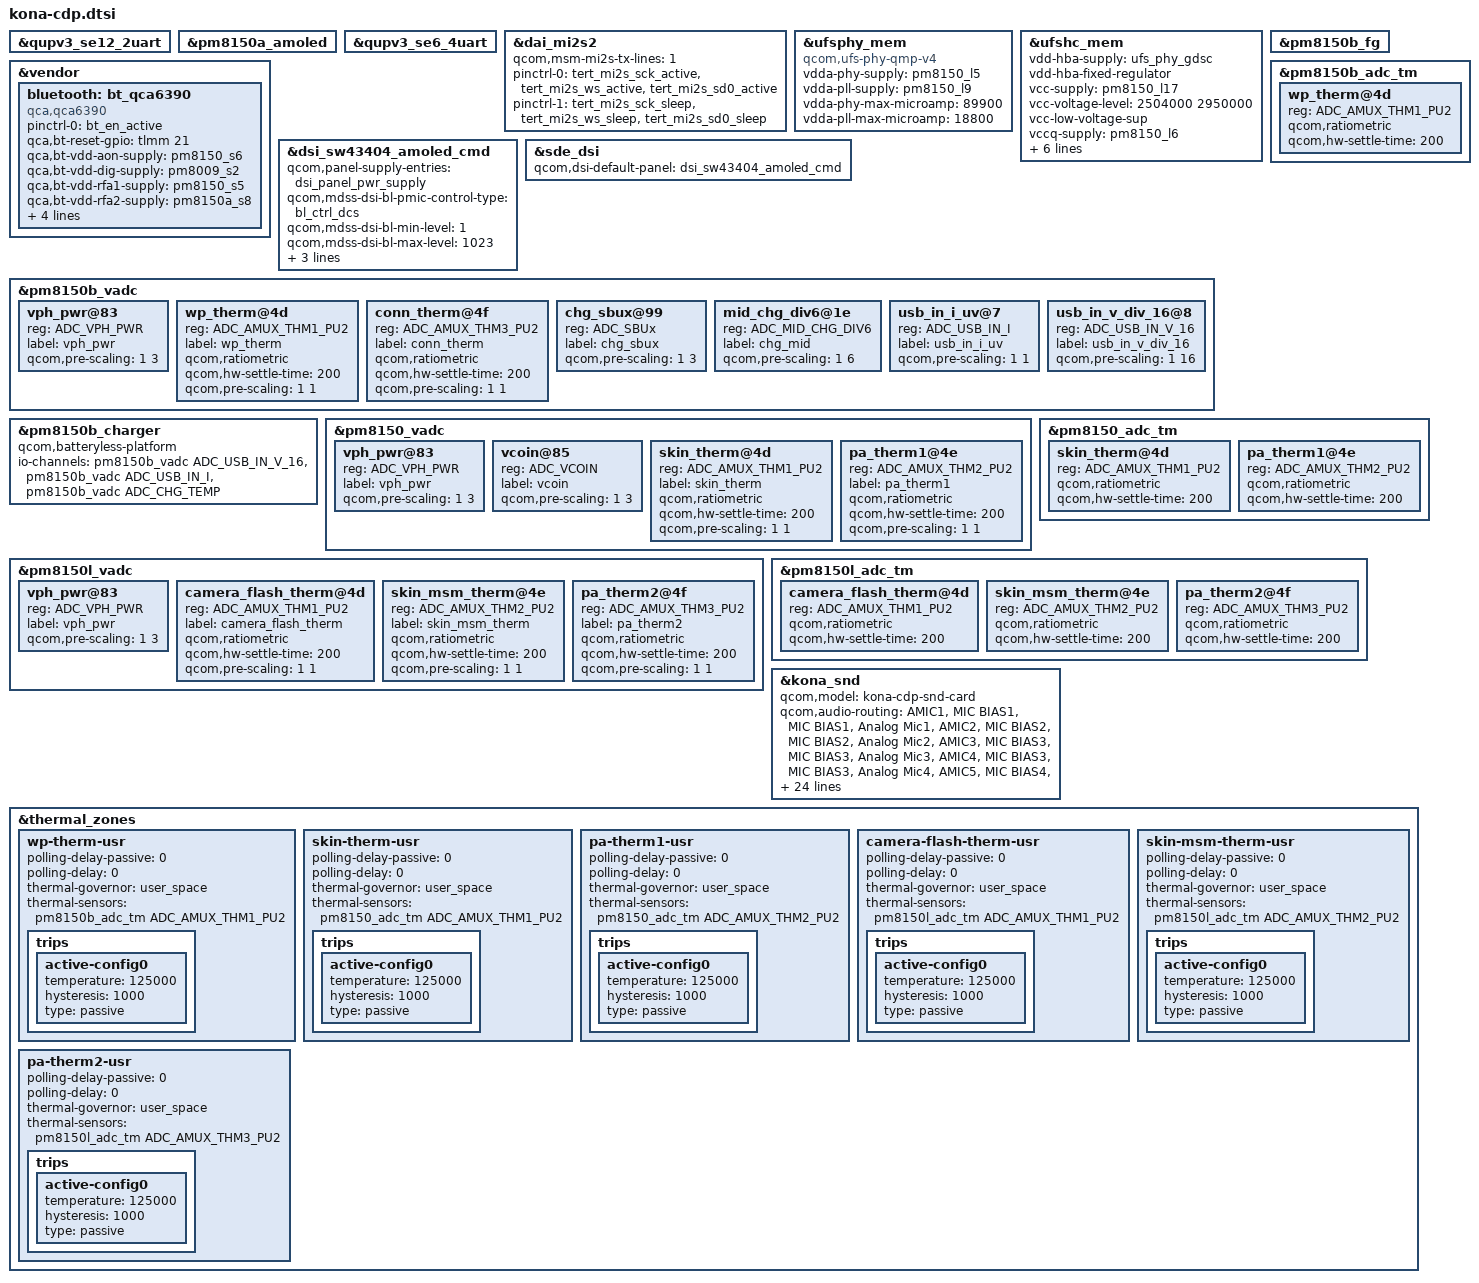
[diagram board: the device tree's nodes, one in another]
// SPDX-License-Identifier: GPL-2.0-only
/*
 * Copyright (c) 2018-2019, The Linux Foundation. All rights reserved.
 */


#include "kona-pmic-overlay.dtsi"
#include "kona-sde-display.dtsi"
#include "kona-camera-sensor-cdp.dtsi"
#include "kona-audio-overlay.dtsi"

&qupv3_se12_2uart {
	status = "ok";
};

&pm8150a_amoled {
	status = "ok";
};

&qupv3_se6_4uart {
	status = "ok";
};

&dai_mi2s2 {
	qcom,msm-mi2s-tx-lines = <1>;
	pinctrl-names = "default", "sleep";
	pinctrl-0 = <&tert_mi2s_sck_active &tert_mi2s_ws_active
			&tert_mi2s_sd0_active>;
	pinctrl-1 = <&tert_mi2s_sck_sleep &tert_mi2s_ws_sleep
			&tert_mi2s_sd0_sleep>;
};

&ufsphy_mem {
	compatible = "qcom,ufs-phy-qmp-v4";

	vdda-phy-supply = <&pm8150_l5>;
	vdda-pll-supply = <&pm8150_l9>;
	vdda-phy-max-microamp = <89900>;
	vdda-pll-max-microamp = <18800>;

	status = "ok";
};

&ufshc_mem {
	vdd-hba-supply = <&ufs_phy_gdsc>;
	vdd-hba-fixed-regulator;
	vcc-supply = <&pm8150_l17>;
	vcc-voltage-level = <2504000 2950000>;
	vcc-low-voltage-sup;
	vccq-supply = <&pm8150_l6>;
	vccq2-supply = <&pm8150_s4>;
	vccq-max-microamp = <800000>;
	vcc-max-microamp = <800000>;
	vccq2-max-microamp = <800000>;

	qcom,vddp-ref-clk-supply = <&pm8150_l6>;
	qcom,vddp-ref-clk-max-microamp = <100>;

	status = "ok";
};

&vendor {
	bluetooth: bt_qca6390 {
		compatible = "qca,qca6390";
		pinctrl-names = "default";
		pinctrl-0 = <&bt_en_active>;
		qca,bt-reset-gpio = <&tlmm 21 0>; /* BT_EN */
		qca,bt-vdd-aon-supply = <&pm8150_s6>;
		qca,bt-vdd-dig-supply = <&pm8009_s2>;
		qca,bt-vdd-rfa1-supply = <&pm8150_s5>;
		qca,bt-vdd-rfa2-supply = <&pm8150a_s8>;

		qca,bt-vdd-aon-voltage-level = <950000 950000>;
		qca,bt-vdd-dig-voltage-level = <950000 952000>;
		qca,bt-vdd-rfa1-voltage-level = <1900000 1900000>;
		qca,bt-vdd-rfa2-voltage-level = <1350000 1350000>;
	};
};

&dsi_sw43404_amoled_cmd {
	qcom,panel-supply-entries = <&dsi_panel_pwr_supply>;
	qcom,mdss-dsi-bl-pmic-control-type = "bl_ctrl_dcs";
	qcom,mdss-dsi-bl-min-level = <1>;
	qcom,mdss-dsi-bl-max-level = <1023>;
	qcom,mdss-brightness-max-level = <255>;
	qcom,platform-te-gpio = <&tlmm 66 0>;
	qcom,platform-reset-gpio = <&tlmm 75 0>;
};

&sde_dsi {
	qcom,dsi-default-panel = <&dsi_sw43404_amoled_cmd>;
};

&pm8150b_vadc {
	#address-cells = <1>;
	#size-cells = <0>;

	vph_pwr@83 {
		reg = <ADC_VPH_PWR>;
		label = "vph_pwr";
		qcom,pre-scaling = <1 3>;
	};

	wp_therm@4d {
		reg = <ADC_AMUX_THM1_PU2>;
		label = "wp_therm";
		qcom,ratiometric;
		qcom,hw-settle-time = <200>;
		qcom,pre-scaling = <1 1>;
	};

	conn_therm@4f {
		reg = <ADC_AMUX_THM3_PU2>;
		label = "conn_therm";
		qcom,ratiometric;
		qcom,hw-settle-time = <200>;
		qcom,pre-scaling = <1 1>;
	};

	chg_sbux@99 {
		reg = <ADC_SBUx>;
		label = "chg_sbux";
		qcom,pre-scaling = <1 3>;
	};

	mid_chg_div6@1e {
		reg = <ADC_MID_CHG_DIV6>;
		label = "chg_mid";
		qcom,pre-scaling = <1 6>;
	};

	usb_in_i_uv@7 {
		reg = <ADC_USB_IN_I>;
		label = "usb_in_i_uv";
		qcom,pre-scaling = <1 1>;
	};

	usb_in_v_div_16@8 {
		reg = <ADC_USB_IN_V_16>;
		label = "usb_in_v_div_16";
		qcom,pre-scaling = <1 16>;
	};
};

&pm8150b_charger {
	status = "ok";
	qcom,batteryless-platform;
	io-channels = <&pm8150b_vadc ADC_USB_IN_V_16>,
		      <&pm8150b_vadc ADC_USB_IN_I>,
		      <&pm8150b_vadc ADC_CHG_TEMP>;
	io-channel-names = "usb_in_voltage",
			   "usb_in_current",
			   "chg_temp";
};

&pm8150b_fg {
	status = "ok";
};

&pm8150_vadc {
	#address-cells = <1>;
	#size-cells = <0>;

	vph_pwr@83 {
		reg = <ADC_VPH_PWR>;
		label = "vph_pwr";
		qcom,pre-scaling = <1 3>;
	};

	vcoin@85 {
		reg = <ADC_VCOIN>;
		label = "vcoin";
		qcom,pre-scaling = <1 3>;
	};

	skin_therm@4d {
		reg = <ADC_AMUX_THM1_PU2>;
		label = "skin_therm";
		qcom,ratiometric;
		qcom,hw-settle-time = <200>;
		qcom,pre-scaling = <1 1>;
	};

	pa_therm1@4e {
		reg = <ADC_AMUX_THM2_PU2>;
		label = "pa_therm1";
		qcom,ratiometric;
		qcom,hw-settle-time = <200>;
		qcom,pre-scaling = <1 1>;
	};
};

&pm8150l_vadc {
	#address-cells = <1>;
	#size-cells = <0>;

	vph_pwr@83 {
		reg = <ADC_VPH_PWR>;
		label = "vph_pwr";
		qcom,pre-scaling = <1 3>;
	};

	camera_flash_therm@4d {
		reg = <ADC_AMUX_THM1_PU2>;
		label = "camera_flash_therm";
		qcom,ratiometric;
		qcom,hw-settle-time = <200>;
		qcom,pre-scaling = <1 1>;
	};

	skin_msm_therm@4e {
		reg = <ADC_AMUX_THM2_PU2>;
		label = "skin_msm_therm";
		qcom,ratiometric;
		qcom,hw-settle-time = <200>;
		qcom,pre-scaling = <1 1>;
	};

	pa_therm2@4f {
		reg = <ADC_AMUX_THM3_PU2>;
		label = "pa_therm2";
		qcom,ratiometric;
		qcom,hw-settle-time = <200>;
		qcom,pre-scaling = <1 1>;
	};
};

&pm8150b_adc_tm {
	#address-cells = <1>;
	#size-cells = <0>;

	wp_therm@4d {
		reg = <ADC_AMUX_THM1_PU2>;
		qcom,ratiometric;
		qcom,hw-settle-time = <200>;
	};
};

&pm8150_adc_tm {
	#address-cells = <1>;
	#size-cells = <0>;

	skin_therm@4d {
		reg = <ADC_AMUX_THM1_PU2>;
		qcom,ratiometric;
		qcom,hw-settle-time = <200>;
	};

	pa_therm1@4e {
		reg = <ADC_AMUX_THM2_PU2>;
		qcom,ratiometric;
		qcom,hw-settle-time = <200>;
	};
};

&pm8150l_adc_tm {
	#address-cells = <1>;
	#size-cells = <0>;

	camera_flash_therm@4d {
		reg = <ADC_AMUX_THM1_PU2>;
		qcom,ratiometric;
		qcom,hw-settle-time = <200>;
	};

	skin_msm_therm@4e {
		reg = <ADC_AMUX_THM2_PU2>;
		qcom,ratiometric;
		qcom,hw-settle-time = <200>;
	};

	pa_therm2@4f {
		reg = <ADC_AMUX_THM3_PU2>;
		qcom,ratiometric;
		qcom,hw-settle-time = <200>;
	};
};

&kona_snd {
	qcom,model = "kona-cdp-snd-card";
	qcom,audio-routing =
		"AMIC1", "MIC BIAS1",
		"MIC BIAS1", "Analog Mic1",
		"AMIC2", "MIC BIAS2",
		"MIC BIAS2", "Analog Mic2",
		"AMIC3", "MIC BIAS3",
		"MIC BIAS3", "Analog Mic3",
		"AMIC4", "MIC BIAS3",
		"MIC BIAS3", "Analog Mic4",
		"AMIC5", "MIC BIAS4",
		"MIC BIAS4", "Analog Mic5",
		"TX DMIC0", "MIC BIAS3",
		"MIC BIAS3", "Digital Mic0",
		"TX DMIC1", "MIC BIAS3",
		"MIC BIAS3", "Digital Mic1",
		"TX DMIC2", "MIC BIAS1",
		"MIC BIAS1", "Digital Mic2",
		"TX DMIC3", "MIC BIAS1",
		"MIC BIAS1", "Digital Mic3",
		"TX DMIC4", "MIC BIAS4",
		"MIC BIAS4", "Digital Mic4",
		"TX DMIC5", "MIC BIAS4",
		"MIC BIAS4", "Digital Mic5",
		"IN1_HPHL", "HPHL_OUT",
		"IN2_HPHR", "HPHR_OUT",
		"IN3_AUX", "AUX_OUT",
		"TX SWR_ADC0", "ADC1_OUTPUT",
		"TX SWR_ADC2", "ADC2_OUTPUT",
		"TX SWR_ADC3", "ADC3_OUTPUT",
		"TX SWR_ADC4", "ADC4_OUTPUT",
		"TX SWR_DMIC0", "DMIC1_OUTPUT",
		"TX SWR_DMIC1", "DMIC2_OUTPUT",
		"TX SWR_DMIC2", "DMIC3_OUTPUT",
		"TX SWR_DMIC3", "DMIC4_OUTPUT",
		"TX SWR_DMIC4", "DMIC5_OUTPUT",
		"TX SWR_DMIC5", "DMIC6_OUTPUT",
		"TX SWR_DMIC6", "DMIC7_OUTPUT",
		"TX SWR_DMIC7", "DMIC8_OUTPUT",
		"WSA SRC0_INP", "SRC0",
		"WSA_TX DEC0_INP", "TX DEC0 MUX",
		"WSA_TX DEC1_INP", "TX DEC1 MUX",
		"RX_TX DEC0_INP", "TX DEC0 MUX",
		"RX_TX DEC1_INP", "TX DEC1 MUX",
		"RX_TX DEC2_INP", "TX DEC2 MUX",
		"RX_TX DEC3_INP", "TX DEC3 MUX",
		"SpkrLeft IN", "WSA_SPK1 OUT",
		"SpkrRight IN", "WSA_SPK2 OUT";
};

&thermal_zones {
	wp-therm-usr {
		polling-delay-passive = <0>;
		polling-delay = <0>;
		thermal-governor = "user_space";
		thermal-sensors = <&pm8150b_adc_tm ADC_AMUX_THM1_PU2>;
		trips {
			active-config0 {
				temperature = <125000>;
				hysteresis = <1000>;
				type = "passive";
			};
		};
	};

	skin-therm-usr {
		polling-delay-passive = <0>;
		polling-delay = <0>;
		thermal-governor = "user_space";
		thermal-sensors = <&pm8150_adc_tm ADC_AMUX_THM1_PU2>;
		trips {
			active-config0 {
				temperature = <125000>;
				hysteresis = <1000>;
				type = "passive";
			};
		};
	};

	pa-therm1-usr {
		polling-delay-passive = <0>;
		polling-delay = <0>;
		thermal-governor = "user_space";
		thermal-sensors = <&pm8150_adc_tm ADC_AMUX_THM2_PU2>;
		trips {
			active-config0 {
				temperature = <125000>;
				hysteresis = <1000>;
				type = "passive";
			};
		};
	};

	camera-flash-therm-usr {
		polling-delay-passive = <0>;
		polling-delay = <0>;
		thermal-governor = "user_space";
		thermal-sensors = <&pm8150l_adc_tm ADC_AMUX_THM1_PU2>;
		trips {
			active-config0 {
				temperature = <125000>;
				hysteresis = <1000>;
				type = "passive";
			};
		};
	};

	skin-msm-therm-usr {
		polling-delay-passive = <0>;
		polling-delay = <0>;
		thermal-governor = "user_space";
		thermal-sensors = <&pm8150l_adc_tm ADC_AMUX_THM2_PU2>;
		trips {
			active-config0 {
				temperature = <125000>;
				hysteresis = <1000>;
				type = "passive";
			};
		};
	};

	pa-therm2-usr {
		polling-delay-passive = <0>;
		polling-delay = <0>;
		thermal-governor = "user_space";
		thermal-sensors = <&pm8150l_adc_tm ADC_AMUX_THM3_PU2>;
		trips {
			active-config0 {
				temperature = <125000>;
				hysteresis = <1000>;
				type = "passive";
			};
		};
	};
};
